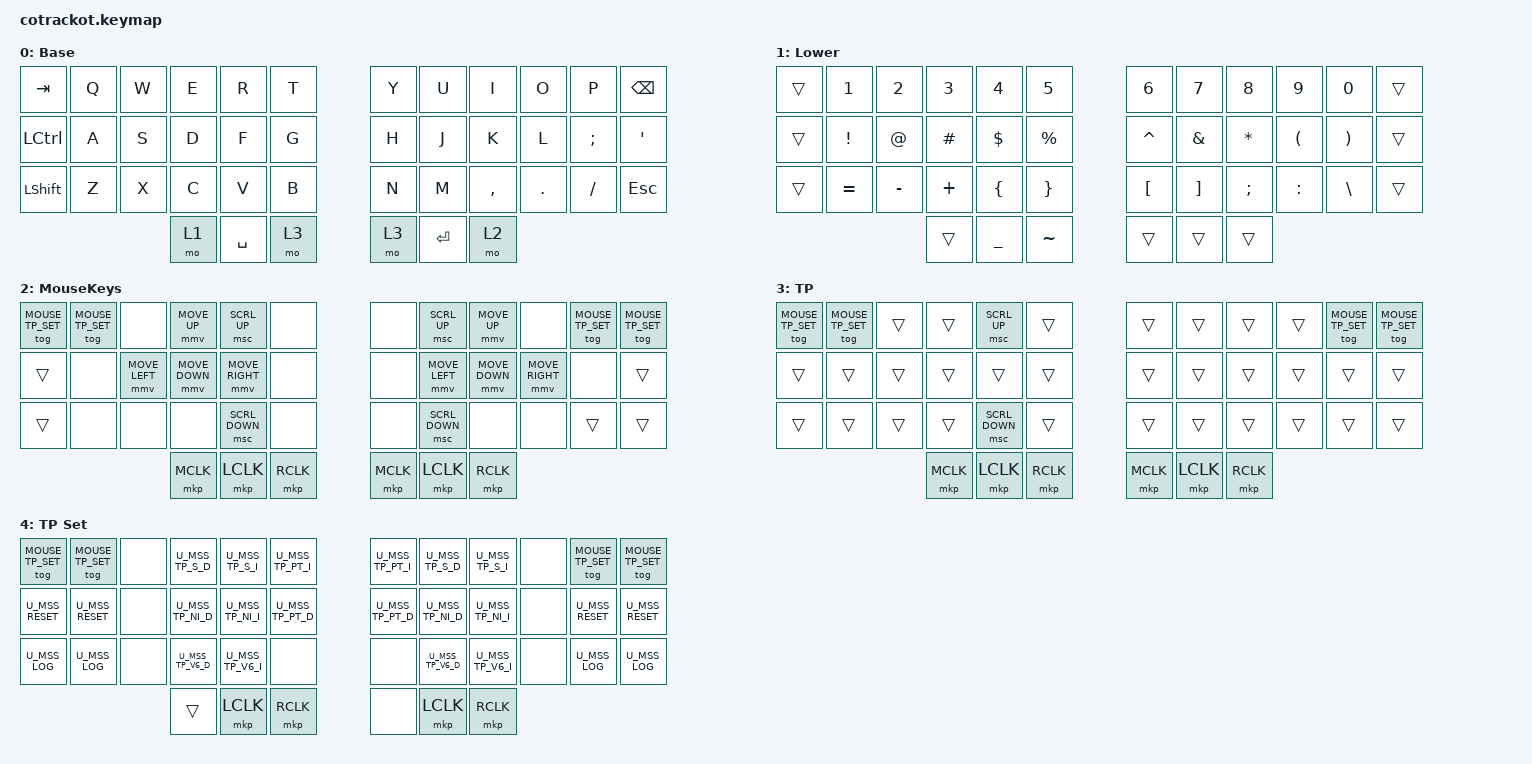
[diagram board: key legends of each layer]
/*
* Copyright (c) 2021 The ZMK Contributors
*
* SPDX-License-Identifier: MIT
*/

#include <behaviors.dtsi>
#include <dt-bindings/zmk/keys.h>
#include <dt-bindings/zmk/bt.h>

#define MAIN 0 
#define SYM 1 
#define NUM 2 
#define MOUSE_TP 3
#define MOUSE_TP_SET 4
#define SCROLL 5

#define HAS_MOUSE_KEYS
#define HAS_MOUSE_TP

#ifdef HAS_MOUSE_KEYS
  #include <dt-bindings/zmk/mouse.h>
  #include <behaviors/mouse_keys.dtsi>
#endif  // HAS_MOUSE_KEYS

#ifdef HAS_MOUSE_TP
  // We store the trackpoint settings in a separate file
  // to make organization a little easier.
  #include "include/mouse_tp.dtsi"
#endif  // HAS_MOUSE_TP

// Adjust layer keys based on enabled features.
//
// This prevents build errors when we build the firmware
// without the mouse keys PR or the TP module.
#ifdef HAS_MOUSE_KEYS
  #define U_THUMB_INNER &mo MOUSE_KEYS
#else
  #define U_THUMB_INNER &none
#endif  // HAS_MOUSE_KEYS

#ifdef HAS_MOUSE_TP
  #define U_TOG_TP_SET &tog MOUSE_TP_SET
#else
  #define U_TOG_TP_SET &none
#endif  // HAS_MOUSE_TP

/ {

  combos { compatible = "zmk,combos"; };

    behaviors {
        hm: homerow_mods {
            compatible = "zmk,behavior-hold-tap";
            label = "HOMEROW_MODS";
            bindings = <&kp>, <&kp>;

            #binding-cells = <2>;
            tapping-term-ms = <200>;
            quick-tap-ms = <150>;
            flavor = "tap-preferred";
        };

        ltq: ltq {
            compatible = "zmk,behavior-hold-tap";
            label = "LTQ";
            bindings = <&mo>, <&kp>;

            #binding-cells = <2>;
            tapping-term-ms = <200>;
            quick-tap-ms = <180>;
        };

        as: auto_shift {
            compatible = "zmk,behavior-hold-tap";
            label = "AUTO_SHIFT";
            bindings = <&kp>, <&kp>;

            #binding-cells = <2>;
            tapping-term-ms = <135>;
            quick-tap-ms = <0>;
        };
    };


    keymap {
    compatible = "zmk,keymap";

    Base_layer {
      display-name = "Base";
      bindings = <
// ╭────────────────────────┬────────────────────────┬────────────────────────┬────────────────────────┬────────────────────────┬────────────────────────╮    ╭────────────────────────┬────────────────────────┬────────────────────────┬───────────────────────┬────────────────────────┬────────────────────────╮
     &kp TAB                  &kp Q                    &kp W                    &kp E                    &kp R                    &kp T                         &kp Y                    &kp U                    &kp I                    &kp O                    &kp P                    &kp BSPC
// ├────────────────────────┼────────────────────────┼────────────────────────┼────────────────────────┼────────────────────────┼────────────────────────┤    ├────────────────────────┼────────────────────────┼────────────────────────┼───────────────────────┼────────────────────────┼────────────────────────┤
     &kp LCTRL                &kp A                    &kp S                    &kp D                    &kp F                    &kp G                         &kp H                    &kp J                    &kp K                    &kp L                    &kp SEMI                 &kp SQT
// ├────────────────────────┼────────────────────────┼────────────────────────┼────────────────────────┼────────────────────────┼────────────────────────┤    ├────────────────────────┼────────────────────────┼────────────────────────┼───────────────────────┼────────────────────────┼────────────────────────┤
     &kp LSHFT                &kp Z                    &kp X                    &kp C                    &kp V                    &kp B                         &kp N                    &kp M                    &kp COMMA                &kp DOT                  &kp SLASH                &kp ESC
// ╰────────────────────────┴────────────────────────┴────────────────────────┴────────────────────────┼────────────────────────┼────────────────────────┤    ├────────────────────────┼────────────────────────┼────────────────────────┼───────────────────────┼────────────────────────┼────────────────────────╯
                                                                                &mo 1                    &kp SPACE                &mo 3                         &mo 3                    &kp RET                  &mo 2
//                                                                            ╰────────────────────────┴────────────────────────┴────────────────────────╯    ╰────────────────────────┴────────────────────────┴────────────────────────╯

      >;
    };


    Lower_layer {
      display-name = "Lower";
      bindings = <
// ╭────────────────────────┬────────────────────────┬────────────────────────┬────────────────────────┬────────────────────────┬────────────────────────╮    ╭────────────────────────┬────────────────────────┬────────────────────────┬────────────────────────┬────────────────────────┬────────────────────────╮
     &trans                   &kp NUMBER_1             &kp NUMBER_2             &kp NUMBER_3             &kp NUMBER_4             &kp NUMBER_5                  &kp NUMBER_6             &kp NUMBER_7             &kp NUMBER_8             &kp NUMBER_9             &kp NUMBER_0              &trans
// ├────────────────────────┼────────────────────────┼────────────────────────┼────────────────────────┼────────────────────────┼────────────────────────┤    ├────────────────────────┼────────────────────────┼────────────────────────┼────────────────────────┼────────────────────────┼────────────────────────┤
     &trans                   &kp EXCLAMATION          &kp AT_SIGN              &kp HASH                 &kp DOLLAR               &kp PERCENT                   &kp CARET                &kp AMPERSAND            &kp ASTERISK             &kp LEFT_PARENTHESIS     &kp RIGHT_PARENTHESIS     &trans
// ├────────────────────────┼────────────────────────┼────────────────────────┼────────────────────────┼────────────────────────┼────────────────────────┤    ├────────────────────────┼────────────────────────┼────────────────────────┼────────────────────────┼────────────────────────┼────────────────────────┤
     &trans                   &kp EQUAL                &kp MINUS                &kp PLUS                 &kp LEFT_BRACE           &kp RIGHT_BRACE               &kp LEFT_BRACKET         &kp RIGHT_BRACKET        &kp SEMICOLON            &kp COLON                &kp BACKSLASH             &trans
// ╰────────────────────────┴────────────────────────┴────────────────────────┴────────────────────────┼────────────────────────┼────────────────────────┤    ├────────────────────────┼────────────────────────┼────────────────────────┼────────────────────────┴────────────────────────┼────────────────────────╯
                                                                                &trans                   &kp UNDERSCORE           &kp TILDE                     &trans                    &trans                  &trans
//                                                                            ╰────────────────────────┴────────────────────────┴────────────────────────╯    ╰────────────────────────┴────────────────────────┴────────────────────────╯
      >;
    };

#ifdef HAS_MOUSE_KEYS

    MouseKeys_layer {
      display-name = "MouseKeys";
      bindings = <
// ╭────────────────────────┬────────────────────────┬────────────────────────┬────────────────────────┬────────────────────────┬────────────────────────╮    ╭────────────────────────┬────────────────────────┬────────────────────────┬────────────────────────┬────────────────────────┬────────────────────────╮
     U_TOG_TP_SET             U_TOG_TP_SET             &none                    &mmv MOVE_UP             &msc SCRL_UP             &none                         &none                    &msc SCRL_UP             &mmv MOVE_UP             &none                    U_TOG_TP_SET              U_TOG_TP_SET
// ├────────────────────────┼────────────────────────┼────────────────────────┼────────────────────────┼────────────────────────┼────────────────────────┤    ├────────────────────────┼────────────────────────┼────────────────────────┼────────────────────────┼────────────────────────┼────────────────────────┤
     &trans                   &none                    &mmv MOVE_LEFT           &mmv MOVE_DOWN           &mmv MOVE_RIGHT          &none                         &none                    &mmv MOVE_LEFT           &mmv MOVE_DOWN           &mmv MOVE_RIGHT          &none                     &trans
// ├────────────────────────┼────────────────────────┼────────────────────────┼────────────────────────┼────────────────────────┼────────────────────────┤    ├────────────────────────┼────────────────────────┼────────────────────────┼────────────────────────┼────────────────────────┼────────────────────────┤
     &trans                   &none                    &none                    &none                    &msc SCRL_DOWN           &none                         &none                    &msc SCRL_DOWN           &none                    &none                    &trans                    &trans
// ╰────────────────────────┴────────────────────────┴────────────────────────┴────────────────────────┼────────────────────────┼────────────────────────┤    ├────────────────────────┼────────────────────────┼────────────────────────┼────────────────────────┴────────────────────────┼────────────────────────╯
                                                                                &mkp MCLK                &mkp LCLK                &mkp RCLK                     &mkp MCLK                &mkp LCLK                &mkp RCLK
//                                                                            ╰────────────────────────┴────────────────────────┴────────────────────────╯    ╰────────────────────────┴────────────────────────┴────────────────────────╯
      >;
    };

#endif

#ifdef HAS_MOUSE_TP

    // Automatically activated when the mouse or trackpoint moves.
    // Configured in `include/mouse_tp.dtsi`.
    MouseTP_layer {
      display-name = "TP";
      bindings = <
// ╭────────────────────────┬────────────────────────┬────────────────────────┬────────────────────────┬────────────────────────┬────────────────────────╮    ╭────────────────────────┬────────────────────────┬────────────────────────┬────────────────────────┬────────────────────────┬────────────────────────╮
     U_TOG_TP_SET             U_TOG_TP_SET             &trans                   &trans                   &msc SCRL_UP             &trans                        &trans                   &trans                   &trans                   &trans                   U_TOG_TP_SET              U_TOG_TP_SET
// ├────────────────────────┼────────────────────────┼────────────────────────┼────────────────────────┼────────────────────────┼────────────────────────┤    ├────────────────────────┼────────────────────────┼────────────────────────┼────────────────────────┼────────────────────────┼────────────────────────┤
     &trans                   &trans                   &trans                   &trans                   &trans                   &trans                        &trans                   &trans                   &trans                   &trans                   &trans                    &trans
// ├────────────────────────┼────────────────────────┼────────────────────────┼────────────────────────┼────────────────────────┼────────────────────────┤    ├────────────────────────┼────────────────────────┼────────────────────────┼────────────────────────┼────────────────────────┼────────────────────────┤
     &trans                   &trans                   &trans                   &trans                   &msc SCRL_DOWN           &trans                        &trans                   &trans                   &trans                   &trans                   &trans                    &trans
// ╰────────────────────────┴────────────────────────┴────────────────────────┴────────────────────────┼────────────────────────┼────────────────────────┤    ├────────────────────────┼────────────────────────┼────────────────────────┼────────────────────────┴────────────────────────┼────────────────────────╯
                                                                                &mkp MCLK                &mkp LCLK                &mkp RCLK                     &mkp MCLK                &mkp LCLK                &mkp RCLK
//                                                                            ╰────────────────────────┴────────────────────────┴────────────────────────╯    ╰────────────────────────┴────────────────────────┴────────────────────────╯
      >;
    };

    // You can find the defines for the actual key press behaviors in `include/mouse_tp.dtsi`.
    MouseSettings_layer {
      display-name = "TP Set";
      bindings = <
// ╭────────────────────────┬────────────────────────┬────────────────────────┬────────────────────────┬────────────────────────┬────────────────────────╮    ╭────────────────────────┬────────────────────────┬────────────────────────┬────────────────────────┬────────────────────────┬────────────────────────╮
     U_TOG_TP_SET             U_TOG_TP_SET             &none                    U_MSS_TP_S_D             U_MSS_TP_S_I             U_MSS_TP_PT_I                 U_MSS_TP_PT_I            U_MSS_TP_S_D             U_MSS_TP_S_I             &none                    U_TOG_TP_SET              U_TOG_TP_SET
// ├────────────────────────┼────────────────────────┼────────────────────────┼────────────────────────┼────────────────────────┼────────────────────────┤    ├────────────────────────┼────────────────────────┼────────────────────────┼────────────────────────┼────────────────────────┼────────────────────────┤
     U_MSS_RESET              U_MSS_RESET              &none                    U_MSS_TP_NI_D            U_MSS_TP_NI_I            U_MSS_TP_PT_D                 U_MSS_TP_PT_D            U_MSS_TP_NI_D            U_MSS_TP_NI_I            &none                    U_MSS_RESET               U_MSS_RESET
// ├────────────────────────┼────────────────────────┼────────────────────────┼────────────────────────┼────────────────────────┼────────────────────────┤    ├────────────────────────┼────────────────────────┼────────────────────────┼────────────────────────┼────────────────────────┼────────────────────────┤
     U_MSS_LOG                U_MSS_LOG                &none                    U_MSS_TP_V6_D            U_MSS_TP_V6_I            &none                         &none                    U_MSS_TP_V6_D            U_MSS_TP_V6_I            &none                    U_MSS_LOG                 U_MSS_LOG
// ╰────────────────────────┴────────────────────────┴────────────────────────┴────────────────────────┼────────────────────────┼────────────────────────┤    ├────────────────────────┼────────────────────────┼────────────────────────┼────────────────────────┴────────────────────────┼────────────────────────╯
                                                                                &trans                   &mkp LCLK                &mkp RCLK                     &none                    &mkp LCLK                &mkp RCLK
//                                                                            ╰────────────────────────┴────────────────────────┴────────────────────────╯    ╰────────────────────────┴────────────────────────┴────────────────────────╯
      >;
    };

#endif
  };
};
